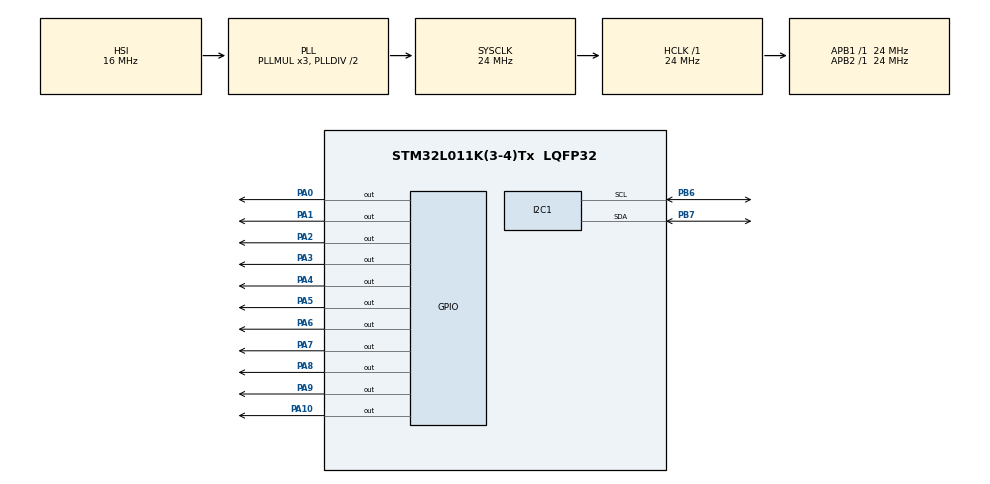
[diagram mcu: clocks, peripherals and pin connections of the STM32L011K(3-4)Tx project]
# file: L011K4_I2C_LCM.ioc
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Mcu.Family=STM32L0
RCC.MSI_VALUE=2097000
RCC.SYSCLKSource=RCC_SYSCLKSOURCE_PLLCLK
ProjectManager.StackSize=0x400
NVIC.I2C1_IRQn=true\:0\:0\:false\:false\:true\:true\:true
PA13.Signal=SYS_SWDIO
RCC.HSI16_VALUE=16000000
ProjectManager.TargetToolchain=STM32CubeIDE
RCC.HCLKFreq_Value=24000000
RCC.APB2TimFreq_Value=24000000
PA9.Signal=GPIO_Output
PB6.Signal=I2C1_SCL
I2C1.Timing=0x00506682
PB6.Mode=I2C
RCC.LSE_VALUE=32768
PA1.Signal=GPIO_Output
RCC.AHBFreq_Value=24000000
PA5.Signal=GPIO_Output
RCC.HSE_VALUE=8000000
board=custom
RCC.VCOOutputFreq_Value=48000000
PA0-CK_IN.Signal=GPIO_Output
RCC.APB2Freq_Value=24000000
PA14.Mode=Serial_Wire
PB7.Signal=I2C1_SDA
PA8.Signal=GPIO_Output
PA13.Mode=Serial_Wire
Mcu.Name=STM32L011K(3-4)Tx
PA2.Signal=GPIO_Output
I2C1.OwnAddress=56
PA4.Signal=GPIO_Output
RCC.SYSCLKFreq_VALUE=24000000
Mcu.Package=LQFP32
PA6.Signal=GPIO_Output
PB7.Mode=I2C
PA10.Signal=GPIO_Output
PA14.Signal=SYS_SWCLK
ProjectManager.HeapSize=0x200
RCC.HSI_VALUE=16000000
RCC.APB1TimFreq_Value=24000000
RCC.APB1Freq_Value=24000000
PA3.Signal=GPIO_Output
PA7.Signal=GPIO_Output

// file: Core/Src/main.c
/* USER CODE BEGIN Header */
/**
  ******************************************************************************
  * @file           : main.c
  * @brief          : Main program body
  ******************************************************************************
  * @attention
  *
  * <h2><center>&copy; Copyright (c) 2021 STMicroelectronics.
  * All rights reserved.</center></h2>
  *
  * This software component is licensed by ST under BSD 3-Clause license,
  * the "License"; You may not use this file except in compliance with the
  * License. You may obtain a copy of the License at:
  *                        opensource.org/licenses/BSD-3-Clause
  *
  ******************************************************************************
  */
/* USER CODE END Header */
#include "main.h"

/* USER CODE BEGIN Includes */

#include "LCM_Task.h"

/* USER CODE END Includes */

I2C_HandleTypeDef hi2c1;

void SystemClock_Config(void);
static void MX_GPIO_Init(void);
static void MX_I2C1_Init(void);

int main(void)
{

  /* MCU Configuration--------------------------------------------------------*/

  /* Reset of all peripherals, Initializes the Flash interface and the Systick. */
  HAL_Init();

  /* Configure the system clock */
  SystemClock_Config();

  /* Initialize all configured peripherals */
  MX_GPIO_Init();
  MX_I2C1_Init();
  /* USER CODE BEGIN 2 */

  //
  LCM_Init();

  /* USER CODE END 2 */

  /* Infinite loop */
  while (1)
  {

    /* USER CODE BEGIN 3 */

	  // LCM update task.
	  LCM_Task();

  }
  /* USER CODE END 3 */
}

void SystemClock_Config(void)
{
  RCC_OscInitTypeDef RCC_OscInitStruct = {0};
  RCC_ClkInitTypeDef RCC_ClkInitStruct = {0};
  RCC_PeriphCLKInitTypeDef PeriphClkInit = {0};

  /** Configure the main internal regulator output voltage
  */
  __HAL_PWR_VOLTAGESCALING_CONFIG(PWR_REGULATOR_VOLTAGE_SCALE1);
  /** Initializes the RCC Oscillators according to the specified parameters
  * in the RCC_OscInitTypeDef structure.
  */
  RCC_OscInitStruct.OscillatorType = RCC_OSCILLATORTYPE_HSI;
  RCC_OscInitStruct.HSIState = RCC_HSI_ON;
  RCC_OscInitStruct.HSICalibrationValue = RCC_HSICALIBRATION_DEFAULT;
  RCC_OscInitStruct.PLL.PLLState = RCC_PLL_ON;
  RCC_OscInitStruct.PLL.PLLSource = RCC_PLLSOURCE_HSI;
  RCC_OscInitStruct.PLL.PLLMUL = RCC_PLLMUL_3;
  RCC_OscInitStruct.PLL.PLLDIV = RCC_PLLDIV_2;
  if (HAL_RCC_OscConfig(&RCC_OscInitStruct) != HAL_OK)
  {
    Error_Handler();
  }
  /** Initializes the CPU, AHB and APB buses clocks
  */
  RCC_ClkInitStruct.ClockType = RCC_CLOCKTYPE_HCLK|RCC_CLOCKTYPE_SYSCLK
                              |RCC_CLOCKTYPE_PCLK1|RCC_CLOCKTYPE_PCLK2;
  RCC_ClkInitStruct.SYSCLKSource = RCC_SYSCLKSOURCE_PLLCLK;
  RCC_ClkInitStruct.AHBCLKDivider = RCC_SYSCLK_DIV1;
  RCC_ClkInitStruct.APB1CLKDivider = RCC_HCLK_DIV1;
  RCC_ClkInitStruct.APB2CLKDivider = RCC_HCLK_DIV1;

  if (HAL_RCC_ClockConfig(&RCC_ClkInitStruct, FLASH_LATENCY_1) != HAL_OK)
  {
    Error_Handler();
  }
  PeriphClkInit.PeriphClockSelection = RCC_PERIPHCLK_I2C1;
  PeriphClkInit.I2c1ClockSelection = RCC_I2C1CLKSOURCE_PCLK1;
  if (HAL_RCCEx_PeriphCLKConfig(&PeriphClkInit) != HAL_OK)
  {
    Error_Handler();
  }
}

static void MX_I2C1_Init(void)
{

  /* USER CODE BEGIN I2C1_Init 0 */

	__HAL_RCC_I2C1_CLK_ENABLE();

  /* USER CODE END I2C1_Init 0 */

  hi2c1.Instance = I2C1;
  hi2c1.Init.Timing = 0x00506682;
  hi2c1.Init.OwnAddress1 = 112;
  hi2c1.Init.AddressingMode = I2C_ADDRESSINGMODE_7BIT;
  hi2c1.Init.DualAddressMode = I2C_DUALADDRESS_DISABLE;
  hi2c1.Init.OwnAddress2 = 0;
  hi2c1.Init.OwnAddress2Masks = I2C_OA2_NOMASK;
  hi2c1.Init.GeneralCallMode = I2C_GENERALCALL_DISABLE;
  hi2c1.Init.NoStretchMode = I2C_NOSTRETCH_DISABLE;
  if (HAL_I2C_Init(&hi2c1) != HAL_OK)
  {
    Error_Handler();
  }
  /** Configure Analogue filter
  */
  if (HAL_I2CEx_ConfigAnalogFilter(&hi2c1, I2C_ANALOGFILTER_ENABLE) != HAL_OK)
  {
    Error_Handler();
  }
  /** Configure Digital filter
  */
  if (HAL_I2CEx_ConfigDigitalFilter(&hi2c1, 0) != HAL_OK)
  {
    Error_Handler();
  }
  /* USER CODE BEGIN I2C1_Init 2 */

  // Stop, ADDR, RXNE interrupt enable.
  I2C1->CR1 |= 0x0000002c;
  // Enable IRQ.
  NVIC_EnableIRQ( I2C1_IRQn );
  // Enable I2C.
  I2C1->CR1 |= 0x00000001;

  /* USER CODE END I2C1_Init 2 */

}

static void MX_GPIO_Init(void)
{
  GPIO_InitTypeDef GPIO_InitStruct = {0};

  /* GPIO Ports Clock Enable */
  __HAL_RCC_GPIOA_CLK_ENABLE();
  __HAL_RCC_GPIOB_CLK_ENABLE();

  /*Configure GPIO pin Output Level */
  HAL_GPIO_WritePin(GPIOA, GPIO_PIN_0|GPIO_PIN_1|GPIO_PIN_2|GPIO_PIN_3
                          |GPIO_PIN_4|GPIO_PIN_5|GPIO_PIN_6|GPIO_PIN_7
                          |GPIO_PIN_8|GPIO_PIN_9|GPIO_PIN_10, GPIO_PIN_RESET);

  /*Configure GPIO pins : PA0 PA1 PA2 PA3
                           PA4 PA5 PA6 PA7
                           PA8 PA9 PA10 */
  GPIO_InitStruct.Pin = GPIO_PIN_0|GPIO_PIN_1|GPIO_PIN_2|GPIO_PIN_3
                          |GPIO_PIN_4|GPIO_PIN_5|GPIO_PIN_6|GPIO_PIN_7
                          |GPIO_PIN_8|GPIO_PIN_9|GPIO_PIN_10;
  GPIO_InitStruct.Mode = GPIO_MODE_OUTPUT_PP;
  GPIO_InitStruct.Pull = GPIO_NOPULL;
  GPIO_InitStruct.Speed = GPIO_SPEED_FREQ_LOW;
  HAL_GPIO_Init(GPIOA, &GPIO_InitStruct);

}

void Error_Handler(void)
{
  __disable_irq();
  while (1)
  {
  }
}

/************************ (C) COPYRIGHT STMicroelectronics *****END OF FILE****/
